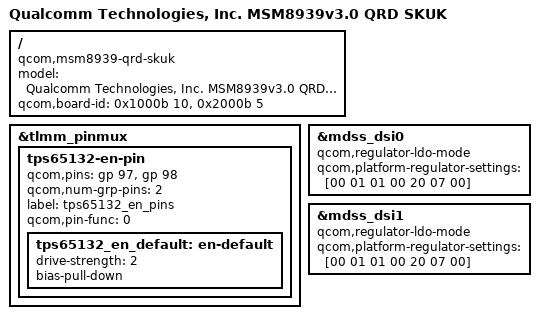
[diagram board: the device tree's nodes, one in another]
/* Copyright (c) 2014, The Linux Foundation. All rights reserved.
 *
 * This program is free software; you can redistribute it and/or modify
 * it under the terms of the GNU General Public License version 2 and
 * only version 2 as published by the Free Software Foundation.
 *
 * This program is distributed in the hope that it will be useful,
 * but WITHOUT ANY WARRANTY; without even the implied warranty of
 * MERCHANTABILITY or FITNESS FOR A PARTICULAR PURPOSE.  See the
 * GNU General Public License for more details.
 */

/dts-v1/;

#include "msm8939-v3.0.dtsi"
#include "msm8939-qrd-skuk.dtsi"
#include "namek.dtsi"

/ {
	model = "Qualcomm Technologies, Inc. MSM8939v3.0 QRD SKUK";
	compatible = "qcom,msm8939-qrd-skuk", "qcom,msm8939-qrd", "qcom,msm8939", "qcom,qrd";
	qcom,board-id = <0x1000b 10>, <0x2000b 5>;
};

&tlmm_pinmux {
	tps65132-en-pin {
		qcom,pins = <&gp 97>, <&gp 98>;
		qcom,num-grp-pins = <2>;
		label = "tps65132_en_pins";
		qcom,pin-func = <0>;

		tps65132_en_default: en-default {
			drive-strength = <2>;
			bias-pull-down;
		};
	};
};

&mdss_dsi0 {
	qcom,regulator-ldo-mode;
	qcom,platform-regulator-settings = [00 01 01 00 20 07 00];
};

&mdss_dsi1 {
	qcom,regulator-ldo-mode;
	qcom,platform-regulator-settings = [00 01 01 00 20 07 00];
};
